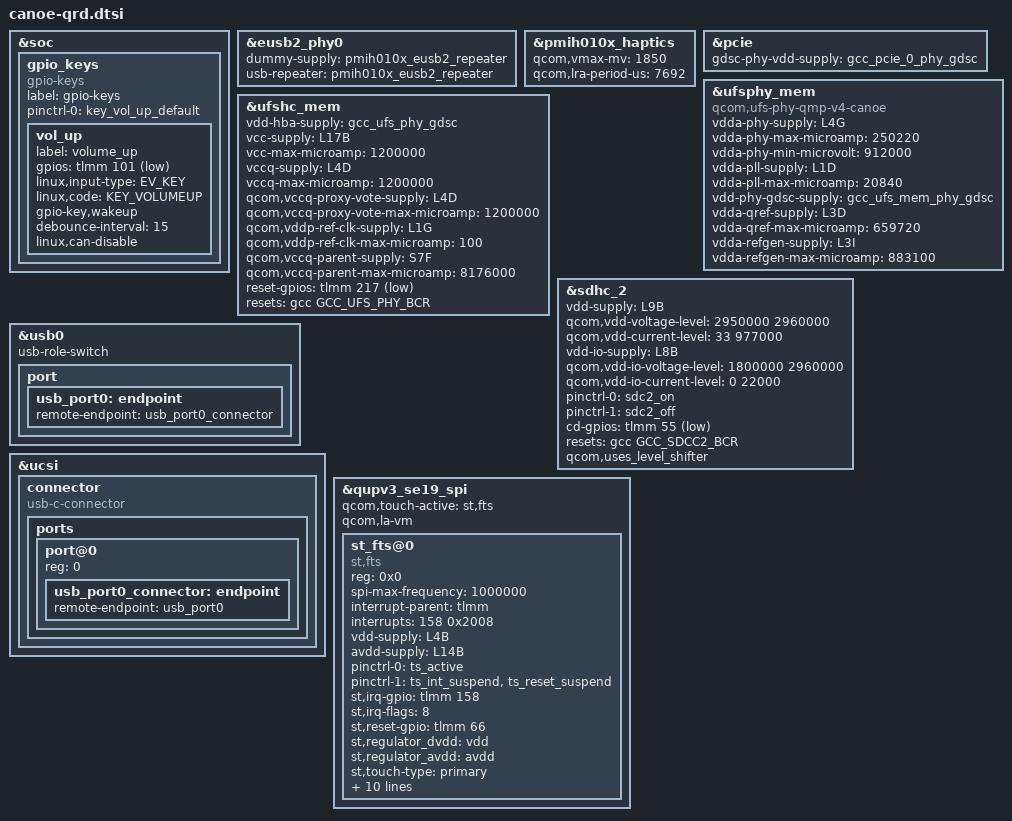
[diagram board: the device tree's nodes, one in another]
// SPDX-License-Identifier: BSD-3-Clause
/*
 * Copyright (c) 2024 Qualcomm Innovation Center, Inc. All rights reserved.
 */

#include <dt-bindings/gpio/gpio.h>
#include <dt-bindings/clock/qcom,gcc-canoe.h>
#include <dt-bindings/input/input.h>

#include "canoe-pmic-overlay.dtsi"
#include "canoe-thermal-overlay.dtsi"

&soc {
	gpio_keys {
		compatible = "gpio-keys";
		label = "gpio-keys";

		pinctrl-names = "default";
		pinctrl-0 = <&key_vol_up_default>;

		vol_up {
			label = "volume_up";
			gpios = <&tlmm 101 GPIO_ACTIVE_LOW>;
			linux,input-type = <EV_KEY>;
			linux,code = <KEY_VOLUMEUP>;
			gpio-key,wakeup;
			debounce-interval = <15>;
			linux,can-disable;
		};
	};
};

&eusb2_phy0 {
	dummy-supply = <&pmih010x_eusb2_repeater>;
	usb-repeater = <&pmih010x_eusb2_repeater>;
};

&pmih010x_haptics {
	qcom,vmax-mv = <1850>;
	qcom,lra-period-us = <7692>;
};

&pcie {
	gdsc-phy-vdd-supply = <&gcc_pcie_0_phy_gdsc>;
};

&ufsphy_mem {
	compatible = "qcom,ufs-phy-qmp-v4-canoe";

	/* VDDA_UFS_CORE */
	vdda-phy-supply = <&L4G>;
	vdda-phy-max-microamp = <250220>;
	/*
	 * Platforms supporting Gear 5 && Rate B require a different
	 * voltage supply. Check the Power Grid document.
	 */
	vdda-phy-min-microvolt = <912000>;

	/* VDDA_UFS_0_1P2 */
	vdda-pll-supply = <&L1D>;
	vdda-pll-max-microamp = <20840>;

	/* Phy GDSC for VDD_MX, always on */
	vdd-phy-gdsc-supply = <&gcc_ufs_mem_phy_gdsc>;

	/* Qref power supply, Refer Qref diagram */
	vdda-qref-supply = <&L3D>;
	vdda-qref-max-microamp = <659720>;

	/*
	 * Refer to Canoe's Power Grid Analysis document.
	 * Add vote for REFGEN_VDD_A_0P9/VDD_A_PCIE_0_0P9 regulator.
	 */
	vdda-refgen-supply = <&L3I>;
	vdda-refgen-max-microamp = <883100>;

	status = "ok";
};

&ufshc_mem {
	vdd-hba-supply = <&gcc_ufs_phy_gdsc>;

	vcc-supply = <&L17B>;
	vcc-max-microamp = <1200000>;

	vccq-supply = <&L4D>;
	vccq-max-microamp = <1200000>;

	qcom,vccq-proxy-vote-supply = <&L4D>;
	qcom,vccq-proxy-vote-max-microamp = <1200000>;

	/* UFS Rst pin is always on. It is shared with VDD_PX14 */
	qcom,vddp-ref-clk-supply = <&L1G>;
	qcom,vddp-ref-clk-max-microamp = <100>;

	qcom,vccq-parent-supply = <&S7F>;
	qcom,vccq-parent-max-microamp = <8176000>;

	reset-gpios = <&tlmm 217 GPIO_ACTIVE_LOW>;

	resets = <&gcc GCC_UFS_PHY_BCR>;
	reset-names = "rst";

	status = "ok";
};

&sdhc_2 {
	vdd-supply = <&L9B>;
	qcom,vdd-voltage-level = <2950000 2960000>;
	qcom,vdd-current-level = <33 977000>;

	vdd-io-supply = <&L8B>;
	qcom,vdd-io-voltage-level = <1800000 2960000>;
	qcom,vdd-io-current-level = <0 22000>;

	pinctrl-names = "default", "sleep";
	pinctrl-0 = <&sdc2_on>;
	pinctrl-1 = <&sdc2_off>;

	cd-gpios = <&tlmm 55 GPIO_ACTIVE_LOW>;

	resets = <&gcc GCC_SDCC2_BCR>;
	reset-names = "core_reset";

	qcom,uses_level_shifter;

	status = "ok";
};

&usb0 {
	usb-role-switch;

	port {
		usb_port0: endpoint {
			remote-endpoint = <&usb_port0_connector>;
		};
	};
};

&ucsi {
	connector {
		compatible = "usb-c-connector";

		ports {
			#address-cells = <1>;
			#size-cells = <0>;

			port@0 {
				reg = <0>;

				usb_port0_connector: endpoint {
					remote-endpoint = <&usb_port0>;
				};
			};
		};
	};
};

&qupv3_se19_spi {
	#address-cells = <1>;
	#size-cells = <0>;
	status = "ok";
	qcom,touch-active = "st,fts";
	qcom,la-vm;

	st_fts@0 {
		compatible = "st,fts";
		reg = <0x0>;
		spi-max-frequency = <1000000>;

		interrupt-parent = <&tlmm>;
		interrupts = <158 0x2008>;
		vdd-supply = <&L4B>;
		avdd-supply = <&L14B>;
		pinctrl-names = "pmx_ts_active", "pmx_ts_suspend";
		pinctrl-0 = <&ts_active>;
		pinctrl-1 = <&ts_int_suspend &ts_reset_suspend>;
		st,irq-gpio = <&tlmm 158 0x2008>;
		st,irq-flags = <8>;
		st,reset-gpio = <&tlmm 66 0x00>;
		st,regulator_dvdd = "vdd";
		st,regulator_avdd = "avdd";

		st,touch-type = "primary";
		st,qts_en;
		qts,trusted-touch-mode = "vm_mode";
		qts,touch-environment = "pvm";
		qts,trusted-touch-type = "primary";
		qts,trusted-touch-spi-irq = <647>;
		qts,trusted-touch-io-bases = <0x1a80000>;
		qts,trusted-touch-io-sizes = <0x1000>;
		qts,trusted-touch-vm-gpio-list = <&tlmm 48 0 &tlmm 49 0 &tlmm 50 0
						&tlmm 51 0 &tlmm 66 0 &tlmm 158 0x2008>;
	};
};
